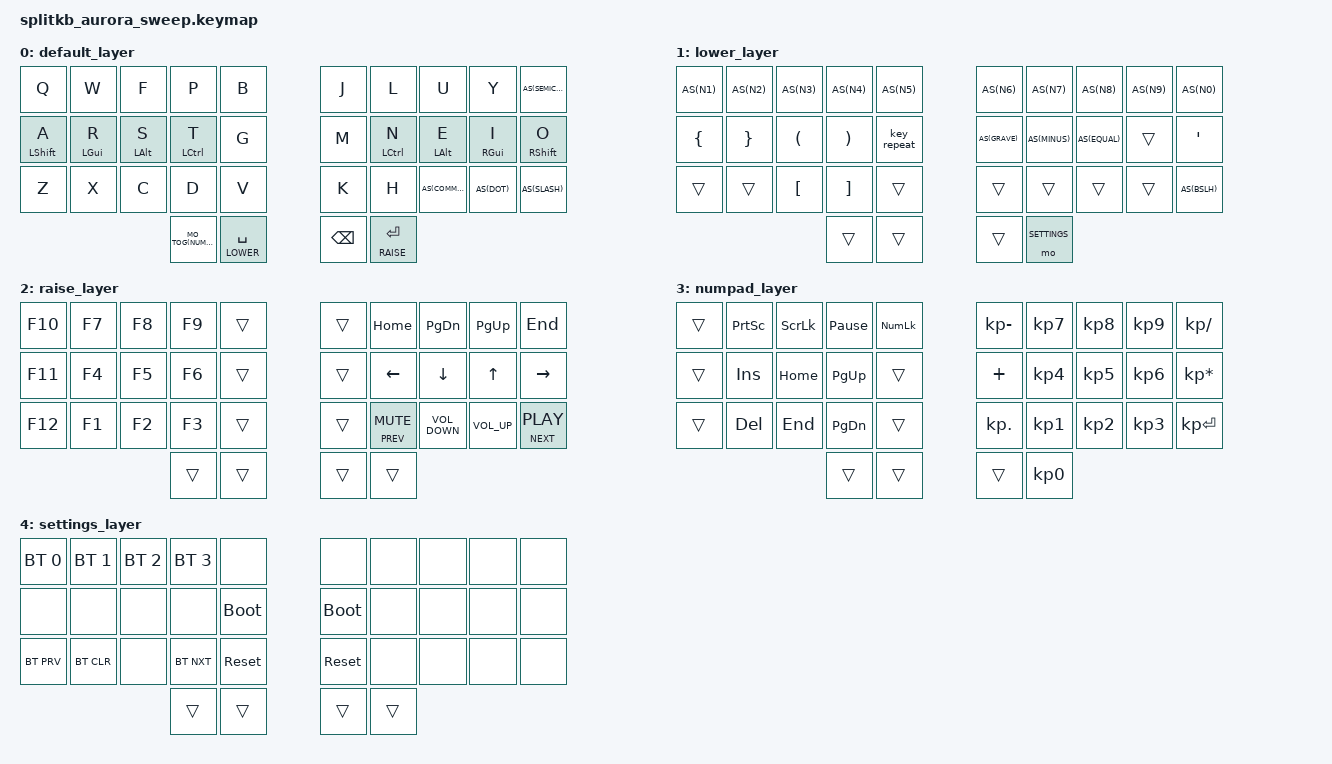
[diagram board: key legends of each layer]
/*
 * Copyright (c) 2022 The ZMK Contributors
 *
 * SPDX-License-Identifier: MIT
 */

#include <behaviors.dtsi>
#include <dt-bindings/zmk/keys.h>
#include <dt-bindings/zmk/bt.h>

// Layer Definitions
	#define DEFAULT	0
	#define LOWER	1
	#define RAISE	2
	#define NUMPAD	3
	#define SETTINGS 4

#define AS(keycode) &as LS(keycode) keycode     // Autoshift Macro
#define MO_TOG(layer) &mo_tog layer layer   // Macro to apply momentary-layer-on-hold/toggle-layer-on-tap to a specific layer

&mt {
	flavor = "tap-preferred";
	tapping_term_ms = <200>;
};

/ {
	behaviors {
		        mo_tog: behavior_mo_tog {
			compatible = "zmk,behavior-hold-tap";
			label = "mo_tog";
			#binding-cells = <2>;
			flavor = "hold-preferred";
			tapping-term-ms = <200>;
			bindings = <&mo>, <&tog>;
		};
			as: auto_shift {
			compatible = "zmk,behavior-hold-tap";
			label = "AUTO_SHIFT";
			#binding-cells = <2>;
			tapping_term_ms = <125>;
			quick_tap_ms = <10>;
			flavor = "tap-preferred";
			bindings = <&kp>, <&kp>;
		};
	};

	combos {
		compatible = "zmk,combos";
		combo_esc {
			timeout-ms = <30>;
			key-positions = <0 1>;
			bindings = <&kp ESC>;
			layers = <0 1 2 3>;
		};

		combo_del {
			timeout-ms = <30>;
			key-positions = <1 2>;
			bindings = <&kp DEL>;
			layers = <0 1 2 3>;
		};

		combo_snip {
			timeout-ms = <30>;
			key-positions = <2 3>;
			bindings = <&kp LS(LG(S))>;
			layers = <0 1 2 3>;
		};

		combo_close{
			timeout-ms = <30>;
			key-positions = <5 6 7>;
			bindings = <&kp LA(F4)>;
			layers = <0 1 2 3>;
		};

		combo_lock{
			timeout-ms = <30>;
			key-positions = <6 7 8>;
			bindings = <&kp LG(L)>;
			layers = <0 1 2 3>;
		};

		combo_cbackspace{
			timeout-ms = <30>;
			key-positions = <8 9>;
			bindings = <&kp LC(BSPC)>;
			layers = <0 1 2 3>;
		};

		combo_tab {
			timeout-ms = <30>;
			key-positions = <10 11>;
			bindings = <&kp TAB>;
			layers = <1 2 3>;
		};

		combo_backtab {
			timeout-ms = <30>;
			key-positions = <11 12>;
			bindings = <&kp LS(TAB)>;
			layers = <1 2 3>;
		};

		combo_quote{
			timeout-ms = <30>;
			key-positions = <18 19>;
			bindings = <AS(SINGLE_QUOTE)>;
			layers = <0 1 2 3>;
		};

		combo_cut{
			timeout-ms = <30>;
			key-positions = <20 21>;
			bindings = <&kp LC(X)>;
			layers = <0 1 2 3>;
		};

		combo_copy{
			timeout-ms = <30>;
			key-positions = <21 22>;
			bindings = <&kp LC(C)>;
			layers = <0 1 2 3>;
		};

		combo_paste{
			timeout-ms = <30>;
			key-positions = <22 23>;
			bindings = <&kp LC(V)>;
			layers = <0 1 2 3>;
		};

		combo_menu{
			timeout-ms = <30>;
			key-positions = <26 27>;
			bindings = <&kp K_APP>;
			layers = <0 1 2 3>;
		};

		combo_backslash{
			timeout-ms = <30>;
			key-positions = <28 29>;
			bindings = <AS(BSLH)>;
			layers = <0>;
		};

		combo_capslock{
			timeout-ms = <30>;
			key-positions = <12 13>;
			bindings = <&kp CAPS>;
			layers = <1 2>;
		};
	};

	keymap {
		compatible = "zmk,keymap";
		default_layer {
				bindings = <
			// ╭───────────────┬───────────────┬───────────────┬───────────────┬───────────────╮╭───────────────┬───────────────┬───────────────┬───────────────┬───────────────╮
				&kp Q		&kp W		&kp F		&kp P		&kp B		&kp J		&kp L		&kp U		&kp Y		AS(SEMICOLON)
			// ├───────────────┼───────────────┼───────────────┼───────────────┼───────────────┤├───────────────┼───────────────┼───────────────┼───────────────┼───────────────┤
				&mt LSHIFT A	&mt LGUI R	&mt LALT S	&mt LCTRL T	&kp G		&kp M		&mt LCTRL N	&mt LALT E	&mt RGUI I	&mt RSHIFT O
			// ├───────────────┼───────────────┼───────────────┼───────────────┼───────────────┤├───────────────┼───────────────┼───────────────┼───────────────┼───────────────┤
				&kp Z		&kp X		&kp C		&kp D		&kp V		&kp K		&kp H		AS(COMMA)	AS(DOT)		AS(SLASH)
			// ╰───────────────┴───────────────┴───────────────┼───────────────┼───────────────┤├───────────────┼───────────────┼───────────────┴───────────────┴───────────────╯
										MO_TOG(NUMPAD)	&lt LOWER SPACE	&kp BACKSPACE	&lt RAISE ENTER
			// 						   ╰───────────────┴───────────────╯╰───────────────┴───────────────╯
				>;
		};

		lower_layer {
				bindings = <
			// ╭───────────────┬───────────────┬───────────────┬───────────────┬───────────────╮╭───────────────┬───────────────┬───────────────┬───────────────┬───────────────╮
				AS(N1)		AS(N2)		AS(N3)		AS(N4)		AS(N5)		AS(N6)		AS(N7)		AS(N8)		AS(N9)		AS(N0)
			// ├───────────────┼───────────────┼───────────────┼───────────────┼───────────────┤├───────────────┼───────────────┼───────────────┼───────────────┼───────────────┤
				&kp LBRC	&kp RBRC	&kp LPAR	&kp RPAR 	&key_repeat	AS(GRAVE)	AS(MINUS)	AS(EQUAL)	&trans		&kp SINGLE_QUOTE
			// ├───────────────┼───────────────┼───────────────┼───────────────┼───────────────┤├───────────────┼───────────────┼───────────────┼───────────────┼───────────────┤
				&trans		&trans		&kp LBKT	&kp RBKT	&trans		&trans		&trans		&trans		&trans		AS(BSLH)
			// ╰───────────────┴───────────────┴───────────────┼───────────────┼───────────────┤├───────────────┼───────────────┼───────────────┴───────────────┴───────────────╯
										&trans		&trans		&trans 		&mo SETTINGS
			// 						   ╰───────────────┴───────────────╯╰───────────────┴───────────────╯
				>;
		};

		raise_layer {
			bindings = <
			// ╭───────────────┬───────────────┬───────────────┬───────────────┬───────────────╮╭───────────────┬───────────────┬───────────────┬───────────────┬───────────────╮
				&kp F10		&kp F7		&kp F8		&kp F9		&trans		&trans		&kp HOME 	&kp PG_DN 	&kp PG_UP	&kp END
			// ├───────────────┼───────────────┼───────────────┼───────────────┼───────────────┤├───────────────┼───────────────┼───────────────┼───────────────┼───────────────┤
				&kp F11		&kp F4		&kp F5		&kp F6		&trans		&trans	 	&kp LEFT	&kp DOWN	&kp UP		&kp RIGHT
			// ├───────────────┼───────────────┼───────────────┼───────────────┼───────────────┤├───────────────┼───────────────┼───────────────┼───────────────┼───────────────┤
				&kp F12		&kp F1		&kp F2		&kp F3		&trans	 	&trans		&mt C_PREV C_MUTE	&kp C_VOLUME_DOWN &kp C_VOLUME_UP &mt C_NEXT C_PLAY
			// ╰───────────────┴───────────────┴───────────────┼───────────────┼───────────────┤├───────────────┼───────────────┼───────────────┴───────────────┴───────────────╯
										&trans		&trans		&trans		&trans
			// 						   ╰───────────────┴───────────────╯╰───────────────┴───────────────╯
			>;
		};

		numpad_layer {
			bindings = <
			// ╭───────────────┬───────────────┬───────────────┬───────────────┬───────────────╮╭───────────────┬───────────────┬───────────────┬───────────────┬───────────────╮
				&trans		&kp PSCRN	&kp SCROLLLOCK	&kp PAUSE_BREAK	&kp KP_NUM	&kp KP_MINUS	&kp KP_N7	&kp KP_N8	&kp KP_N9	&kp KP_SLASH
			// ├───────────────┼───────────────┼───────────────┼───────────────┼───────────────┤├───────────────┼───────────────┼───────────────┼───────────────┼───────────────┤
				&trans		&kp INSERT	&kp HOME	&kp PG_UP	&trans		&kp PLUS	&kp KP_N4	&kp KP_N5	&kp KP_N6	&kp KP_ASTERISK
			// ├───────────────┼───────────────┼───────────────┼───────────────┼───────────────┤├───────────────┼───────────────┼───────────────┼───────────────┼───────────────┤
				&trans		&kp DELETE	&kp END		&kp PG_DN	&trans		&kp KP_DOT	&kp KP_N1	&kp KP_N2	&kp KP_N3	&kp KP_ENTER
			// ╰───────────────┴───────────────┴───────────────┼───────────────┼───────────────┤├───────────────┼───────────────┼───────────────┴───────────────┴───────────────╯
										&trans		&trans		&trans		&kp KP_N0
			// 						   ╰───────────────┴───────────────╯╰───────────────┴───────────────╯
			>;
		};

		settings_layer {
			bindings = <
			// ╭───────────────┬───────────────┬───────────────┬───────────────┬───────────────╮╭───────────────┬───────────────┬───────────────┬───────────────┬───────────────╮
				&bt BT_SEL 0	&bt BT_SEL 1	&bt BT_SEL 2	&bt BT_SEL 3	&none		&none		&none		&none		&none		&none
			// ├───────────────┼───────────────┼───────────────┼───────────────┼───────────────┤├───────────────┼───────────────┼───────────────┼───────────────┼───────────────┤
				&none		&none		&none		&none		&bootloader	&bootloader	&none		&none		&none		&none
			// ├───────────────┼───────────────┼───────────────┼───────────────┼───────────────┤├───────────────┼───────────────┼───────────────┼───────────────┼───────────────┤
				&bt BT_PRV	&bt BT_CLR	&none 		&bt BT_NXT	&sys_reset	&sys_reset	&none		&none		&none		&none
			// ╰───────────────┴───────────────┴───────────────┼───────────────┼───────────────┤├───────────────┼───────────────┼───────────────┴───────────────┴───────────────╯
										&trans		&trans		&trans		&trans
			// 						   ╰───────────────┴───────────────╯╰───────────────┴───────────────╯
			>;
		};
	};
};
